AUTOSAR XML (schema 4-0-3)
package /ComponentTypes
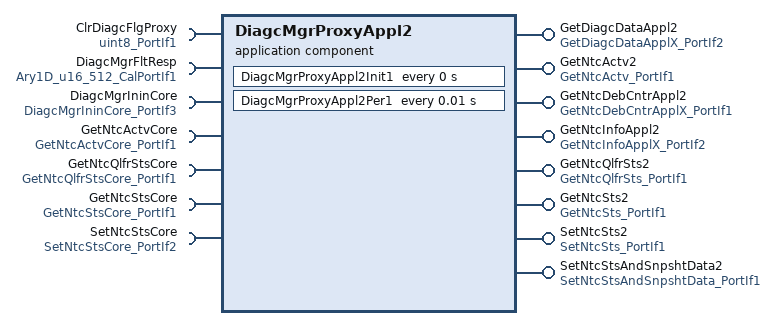
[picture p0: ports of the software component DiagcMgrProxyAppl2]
  application sw component type DiagcMgrProxyAppl2
    8 x provide port, all with server-com-spec{operation=Oper, queue-length=1}:
      GetDiagcDataAppl2: provided-interface=GetDiagcDataApplX_PortIf2
      GetNtcActv2: provided-interface=GetNtcActv_PortIf1
      GetNtcDebCntrAppl2: provided-interface=GetNtcDebCntrApplX_PortIf1
      GetNtcInfoAppl2: provided-interface=GetNtcInfoApplX_PortIf2
      GetNtcQlfrSts2: provided-interface=GetNtcQlfrSts_PortIf1
      GetNtcSts2: provided-interface=GetNtcSts_PortIf1
      SetNtcSts2: provided-interface=SetNtcSts_PortIf1
      SetNtcStsAndSnpshtData2: provided-interface=SetNtcStsAndSnpshtData_PortIf1
    7 x require port:
      ClrDiagcFlgProxy: nonqueued-receiver-com-spec{data-element=Val, filter=data-filter-type=ALWAYS, init-value=0}, required-interface=uint8_PortIf1
      DiagcMgrFltResp: parameter-require-com-spec{init-value=[0, 34560, 34560, 34560, 34560, 34560, 34560, 34560, 34560, 34560, 34560, 34560, 34560, 34560, 34560, 34560, 34560, 34560, 34560, 34560, 34560, 34560, 34560, 34560, 34560, 34560, 34560, 34560, 34560, 34560, 34560, 34560, 34560, 34560, 34560, 34560, 34560, 34560, 34560, 34560, 34560, 34560, 34560, 34560, 34560, 34560, 34560, 34560, 34560, 34560, 34560, 34560, 34560, 34560, 34560, 34560, 34560, 34560, 34560, 34560, 34560, 34560, 34560, 34560, 34560, 34560, 34560, 34560, 34560, 34560, 34560, 34560, 34560, 34560, 34560, 34560, 34560, 34560, 34560, 34560, 34560, 34560, 34560, 34560, 34560, 34560, 34560, 34560, 34560, 34560, 34560, 34560, 34560, 34560, 34560, 34560, 34560, 34560, 34560, 34560, 34560, 34560, 34560, 34560, 34560, 34560, 34560, 34560, 34560, 34560, 34560, 34560, 34560, 34560, 34560, 34560, 34560, 34560, 34560, 34560, 34560, 34560, 34560, 34560, 34560, 34560, 34560, 34560, 34560, 34560, 34560, 34560, 34560, 34560, 34560, 34560, 34560, 34560, 34560, 34560, 34560, 34560, 34560, 34560, 34560, 34560, 34560, 34560, 34560, 34560, 34560, 34560, 34560, 34560, 34560, 34560, 34560, 34560, 34560, 34560, 34560, 34560, 34560, 34560, 34560, 34560, 34560, 34560, 34560, 34560, 34560, 34560, 34560, 34560, 34560, 34560, 34560, 34560, 34560, 34560, 34560, 34560, 34560, 34560, 34560, 34560, 34560, 34560, 34560, 34560, 34560, 34560, 34560, 34560, 34560, 34560, 34560, 34560, 34560, 34560, 34560, 34560, 34560, 34560, 34560, 34560, 34560, 34560, 34560, 34560, 34560, 34560, 34560, 34560, 34560, 34560, 34560, 34560, 34560, 34560, 34560, 34560, 34560, 34560, 34560, 34560, 34560, 34560, 34560, 34560, 34560, 34560, 34560, 34560, 34560, 34560, 34560, 34560, 34560, 34560, 34560, 34560, 34560, 34560, 34560, 34560, 34560, 34560, 34560, 34560, 34560, 34560, 34560, 34560, 34560, 34560, 34560, 34560, 34560, 34560, 34560, 34560, 34560, 34560, 34560, 34560, 34560, 34560, 34560, 34560, 34560, 34560, 34560, 34560, 34560, 34560, 34560, 34560, 34560, 34560, 34560, 34560, 34560, 34560, 34560, 34560, 34560, 34560, 34560, 34560, 34560, 34560, 34560, 34560, 34560, 34560, 34560, 34560, 34560, 34560, 34560, 34560, 34560, 34560, 34560, 34560, 34560, 34560, 34560, 34560, 34560, 34560, 34560, 34560, 34560, 34560, 34560, 34560, 34560, 34560, 34560, 34560, 34560, 34560, 34560, 34560, 34560, 34560, 34560, 34560, 34560, 34560, 34560, 34560, 34560, 34560, 34560, 34560, 34560, 34560, 34560, 34560, 34560, 34560, 34560, 34560, 34560, 34560, 34560, 34560, 34560, 34560, 34560, 34560, 34560, 34560, 34560, 34560, 34560, 34560, 34560, 34560, 34560, 34560, 34560, 34560, 34560, 34560, 34560, 34560, 34560, 34560, 34560, 34560, 34560, 34560, 34560, 34560, 34560, 34560, 34560, 34560, 34560, 34560, 34560, 34560, 34560, 34560, 34560, 34560, 34560, 34560, 34560, 34560, 34560, 34560, 34560, 34560, 34560, 34560, 34560, 34560, 34560, 34560, 34560, 34560, 34560, 34560, 34560, 34560, 34560, 34560, 34560, 34560, 34560, 34560, 34560, 34560, 34560, 34560, 34560, 34560, 34560, 34560, 34560, 34560, 34560, 34560, 34560, 34560, 34560, 34560, 34560, 34560, 34560, 34560, 34560, 34560, 34560, 34560, 34560, 34560, 34560, 34560, 34560, 34560, 34560, 34560, 34560, 34560, 34560, 34560, 34560, 34560, 34560, 34560, 34560, 34560, 34560, 34560, 34560, 34560, 34560, 34560, 34560, 34560, 34560, 34560, 34560, 34560, 34560, 34560, 34560, 34560, 34560, 34560, 34560, 34560, 34560, 34560, 34560, 34560, 34560, 34560, 34560, 34560, 34560, 34560, 34560, 34560, 34560, 34560, 34560, 34560, 34560, 34560, 34560, 34560, 34560, 34560, 34560, 34560, 34560, 34560, 34560, 34560, 34560, 34560, 34560, 34560, 34560, 34560], parameter=Ary1D}, required-interface=Ary1D_u16_512_CalPortIf1
      DiagcMgrIninCore: client-com-spec=Oper, required-interface=DiagcMgrIninCore_PortIf3
      GetNtcActvCore: client-com-spec=Oper, required-interface=GetNtcActvCore_PortIf1
      GetNtcQlfrStsCore: client-com-spec=Oper, required-interface=GetNtcQlfrStsCore_PortIf1
      GetNtcStsCore: client-com-spec=Oper, required-interface=GetNtcStsCore_PortIf1
      SetNtcStsCore: client-com-spec=Oper, required-interface=SetNtcStsCore_PortIf2
    behavior DiagcMgrProxyAppl2_InternalBehavior
      exclusive area DiagcMgrProxyAppl2
      ar-typed-per-instance-memorys:
        5 x data:
          DiagcData2: sw-calibration-access=READ-ONLY, type=DiagcDataRec2
          DiagcMgrNtcInfo2Ary: type=Ary1D_NtcInfoRec4_DiagcMgrProxyAppl2
          DiagcMgrNtcInfo2DebCntrAry: type=Ary1D_s16_DiagcMgrProxyAppl2
          PrevClrNtcFlg2: sw-calibration-access=READ-ONLY, type=uint8
          ProxySetNtcData2: sw-calibration-access=READ-ONLY, type=DiagcDataRec2
      timing event DiagcMgrProxyAppl2_InitEvent: start-on-event=DiagcMgrProxyAppl2Init1, period=0
      timing event TMT_DiagcMgrProxyAppl2Per1: start-on-event=DiagcMgrProxyAppl2Per1, period=0.01
      8 x operation invoked event:
        OIT_GetDiagcDataAppl2_Oper_GetDiagcDataAppl2_Oper: start-on-event=GetDiagcDataAppl2_Oper, operation=GetDiagcDataAppl2.Oper
        OIT_GetNtcActv2_Oper_GetNtcActv2_Oper: start-on-event=GetNtcActv2_Oper, operation=GetNtcActv2.Oper
        OIT_GetNtcDebCntrAppl2_Oper_GetNtcDebCntrAppl2_Oper: start-on-event=GetNtcDebCntrAppl2_Oper, operation=GetNtcDebCntrAppl2.Oper
        OIT_GetNtcInfoAppl2_Oper_GetNtcInfoAppl2_Oper: start-on-event=GetNtcInfoAppl2_Oper, operation=GetNtcInfoAppl2.Oper
        OIT_GetNtcQlfrSts2_Oper_GetNtcQlfrSts2_Oper: start-on-event=GetNtcQlfrSts2_Oper, operation=GetNtcQlfrSts2.Oper
        OIT_GetNtcSts2_Oper_GetNtcSts2_Oper: start-on-event=GetNtcSts2_Oper, operation=GetNtcSts2.Oper
        OIT_SetNtcSts2_Oper_SetNtcSts2_Oper: start-on-event=SetNtcSts2_Oper, operation=SetNtcSts2.Oper
        OIT_SetNtcStsAndSnpshtData2_Oper_SetNtcStsAndSnpshtData2_Oper: start-on-event=SetNtcStsAndSnpshtData2_Oper, operation=SetNtcStsAndSnpshtData2.Oper
      10 x runnable:
        DiagcMgrProxyAppl2Init1
          sync call SC_DiagcMgrIninCore_Oper: operation=DiagcMgrIninCore.Oper, timeout=0
        DiagcMgrProxyAppl2Per1: can-enter-exclusive-area=DiagcMgrProxyAppl2
          data-receive-point-by-arguments:
            access REC_ClrNtcFlg_Val: accessed-variable=ClrDiagcFlgProxy.Val
        GetDiagcDataAppl2_Oper
        GetNtcActv2_Oper: can-be-invoked-concurrently=true
          sync call SC_GetNtcActvCore_Oper: operation=GetNtcActvCore.Oper, timeout=0
        GetNtcDebCntrAppl2_Oper: can-be-invoked-concurrently=true
        GetNtcInfoAppl2_Oper: can-be-invoked-concurrently=true
        GetNtcQlfrSts2_Oper: can-be-invoked-concurrently=true
          sync call SC_GetNtcQlfrStsCore_Oper: operation=GetNtcQlfrStsCore.Oper, timeout=0
        GetNtcSts2_Oper: can-be-invoked-concurrently=true
          sync call SC_GetNtcStsCore_Oper: operation=GetNtcStsCore.Oper, timeout=0
        SetNtcSts2_Oper: can-be-invoked-concurrently=true
          sync call SC_SetNtcStsCore_Oper: operation=SetNtcStsCore.Oper, timeout=0
        SetNtcStsAndSnpshtData2_Oper: can-be-invoked-concurrently=true
          sync call SC_SetNtcStsCore_Oper: operation=SetNtcStsCore.Oper, timeout=0
  swc implementation DiagcMgrProxyAppl2_Implementation: behavior=DiagcMgrProxyAppl2_InternalBehavior
    code-descriptors:
      code Default: artifact-descriptors=autosar-engineering-object={short-label=Default, category=SWSRC}
